# STM32L562 register map
File version: 1.0
CPU: CM33 r0p1, little endian, MPU, FPU, 3 interrupt priority bits
Registers are 32-bit, read-write, reset 0x0 unless marked. A register's access mark holds for its fields unless they carry their own. Offsets are from the block's base; [hi:lo] are bit positions; lines under a group give offsets from that group; {n}, {i} and the like mark numbered series.

## TIM6 — General-purpose-timers
Base 0x40001000
Same registers: TIM7 0x40001400, SEC_TIM6 0x50001000, SEC_TIM7 0x50001400
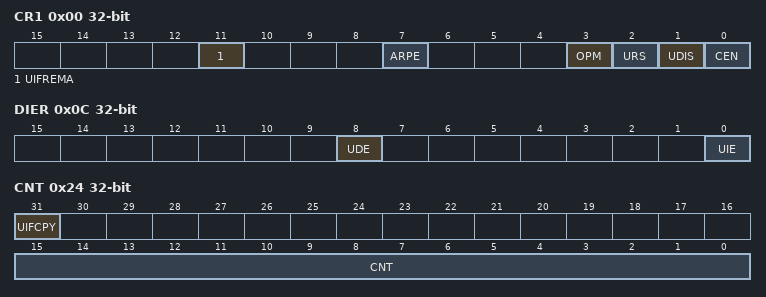
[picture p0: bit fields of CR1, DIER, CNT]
0x00 CR1 — control register 1
  [11] UIFREMA — UIF status bit remapping
  [7] ARPE — Auto-reload preload enable
    0=Disabled (TIMx_APRR register is not buffered); 1=Enabled (TIMx_APRR register is buffered)
  [3] OPM — One-pulse mode
    0=Disabled (Counter is not stopped at update event); 1=Enabled (Counter stops counting at the next update event (clearing the CEN bit))
  [2] URS — Update request source
    0=AnyEvent (Any of counter overflow/underflow, setting UG, or update through slave mode, generates an update interrupt or DMA request); 1=CounterOnly (Only counter overflow/underflow generates an update interrupt or DMA request)
  [1] UDIS — Update disable
    0=Enabled (Update event enabled); 1=Disabled (Update event disabled)
  [0] CEN — Counter enable
    0=Disabled (Counter disabled); 1=Enabled (Counter enabled)
0x04 CR2 — control register 2
  [6:4] MMS — Master mode selection
    0=Reset (Use UG bit from TIMx_EGR register); 1=Enable (Use CNT bit from TIMx_CEN register); 2=Update (Use the update event)
0x0C DIER — DMA/Interrupt enable register
  [8] UDE — Update DMA request enable
    0=Disabled (Update DMA request disabled); 1=Enabled (Update DMA request enabled)
  [0] UIE — Update interrupt enable
    0=Disabled (Update interrupt disabled); 1=Enabled (Update interrupt enabled)
0x10 SR — status register
  [0] UIF write-0-clears — Update interrupt flag
    on read: 0=NoUpdateOccurred; 1=UpdatePending (Update interrupt pending) | on write: 0=Clear flag
0x14 EGR wo — event generation register
  [0] UG — Update generation
    1=Update (Re-initializes the timer counter and generates an update of the registers.)
0x24 CNT — counter
  [31] UIFCPY — UIFCPY or Res
  [15:0] CNT
0x24 CNT16 16-bit (alternate view of CNT) — 16-bit counter register
  [15:0] CNT — counter value
0x28 PSC — prescaler
  [15:0] PSC — Prescaler value
0x2C ARR reset 0xFFFF — auto-reload register
  [15:0] ARR — ARR_bit0

## TSC — Touch sensing controller
Base 0x40024000
Same registers: SEC_TSC 0x50024000
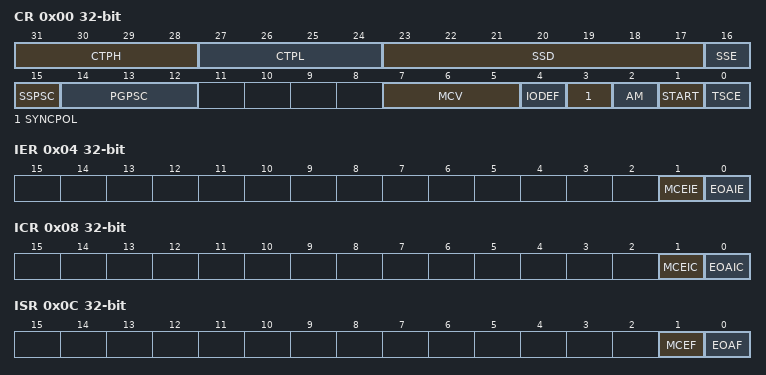
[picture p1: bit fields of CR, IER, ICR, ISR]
0x00 CR — control register
  [31:28] CTPH — Charge transfer pulse high
  [27:24] CTPL — Charge transfer pulse low
  [23:17] SSD — Spread spectrum deviation
  [16] SSE — Spread spectrum enable
    0=Disabled (Spread spectrum disabled); 1=Enabled (Spread spectrum enabled)
  [15] SSPSC — Spread spectrum prescaler
  [14:12] PGPSC — pulse generator prescaler
  [7:5] MCV — Max count value
  [4] IODEF — I/O Default mode
    0=PushPull (I/Os are forced to output push-pull low); 1=Floating (I/Os are in input floating)
  [3] SYNCPOL — Synchronization pin polarity
    0=Falling edge only; 1=Rising edge and high level
  [2] AM — Acquisition mode
    0=Normal acquisition mode (acquisition starts as soon as START bit is set); 1=Synchronized acquisition mode (acquisition starts if START bit is set and when the selected signal is detected on the SYNC input pin)
  [1] START — Start a new acquisition
    0=NoStarted (Acquisition not started); 1=Started (Start a new acquisition)
  [0] TSCE — Touch sensing controller enable
    0=Disabled (Touch sensing controller disabled); 1=Enabled (Touch sensing controller enabled)
0x04 IER — interrupt enable register
  [1] MCEIE — Max count error interrupt enable
    0=Disabled (Max count error interrupt disabled); 1=Enabled (Max count error interrupt enabled)
  [0] EOAIE — End of acquisition interrupt enable
    0=Disabled (End of acquisition interrupt disabled); 1=Enabled (End of acquisition interrupt enabled)
0x08 ICR — interrupt clear register
  [1] MCEIC — Max count error interrupt clear
  [0] EOAIC — End of acquisition interrupt clear
0x0C ISR — interrupt status register
  [1] MCEF — Max count error flag
  [0] EOAF — End of acquisition flag
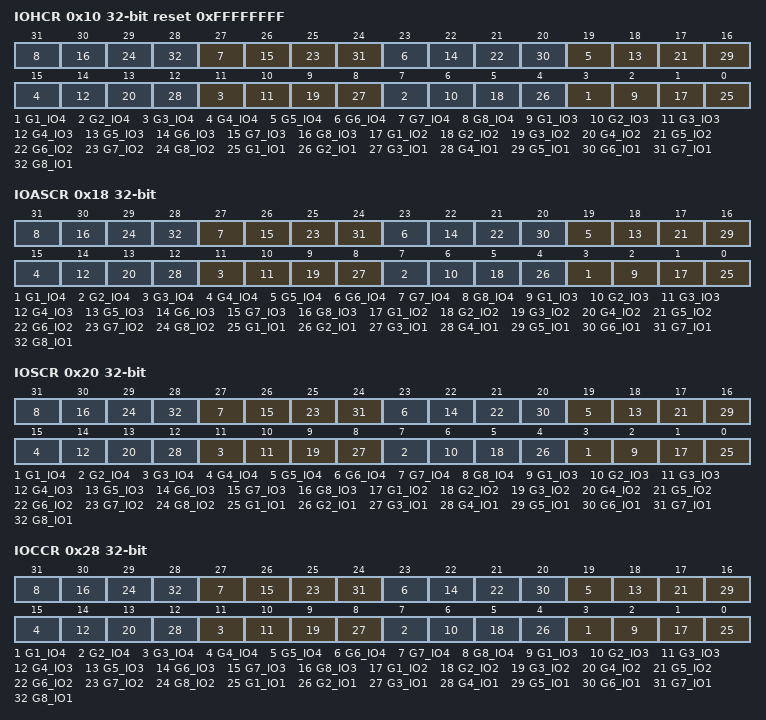
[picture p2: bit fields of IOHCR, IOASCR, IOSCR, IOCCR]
0x10 IOHCR reset 0xFFFFFFFF — I/O hysteresis control register
  [all] fields
    0=Disabled (Gx_IOy Schmitt trigger hysteresis disabled); 1=Enabled (Gx_IOy Schmitt trigger hysteresis enabled)
  [4n-1] G{n}_IO4 (n=1..8) — G{n}_IO4
  [4n-2] G{n}_IO3 (n=1..8) — G{n}_IO3
  [4n-3] G{n}_IO2 (n=1..8) — G{n}_IO2
  [4n-4] G{n}_IO1 (n=1..8) — G{n}_IO1
0x18 IOASCR — I/O analog switch control register
  [all] fields
    0=Disabled (Gx_IOy analog switch disabled (opened)); 1=Enabled (Gx_IOy analog switch enabled (closed))
  [4n-1] G{n}_IO4 (n=1..8) — G{n}_IO4
  [4n-2] G{n}_IO3 (n=1..8) — G{n}_IO3
  [4n-3] G{n}_IO2 (n=1..8) — G{n}_IO2
  [4n-4] G{n}_IO1 (n=1..8) — G{n}_IO1
0x20 IOSCR — I/O sampling control register
  [all] fields
    0=Disabled (Gx_IOy unused); 1=Enabled (Gx_IOy used as sampling capacitor)
  [4n-1] G{n}_IO4 (n=1..8) — G{n}_IO4
  [4n-2] G{n}_IO3 (n=1..8) — G{n}_IO3
  [4n-3] G{n}_IO2 (n=1..8) — G{n}_IO2
  [4n-4] G{n}_IO1 (n=1..8) — G{n}_IO1
0x28 IOCCR — I/O channel control register
  [all] fields
    0=Disabled (Gx_IOy unused); 1=Enabled (Gx_IOy used as channel)
  [4n-1] G{n}_IO4 (n=1..8) — G{n}_IO4
  [4n-2] G{n}_IO3 (n=1..8) — G{n}_IO3
  [4n-3] G{n}_IO2 (n=1..8) — G{n}_IO2
  [4n-4] G{n}_IO1 (n=1..8) — G{n}_IO1
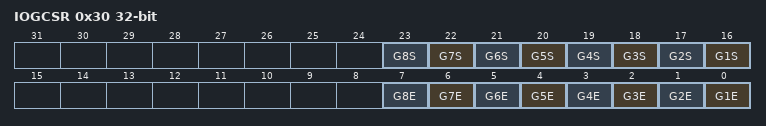
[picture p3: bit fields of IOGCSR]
0x30 IOGCSR access per field — I/O group control status register
  [n+15] G{n}S (n=1..8) ro — Analog I/O group x status
    0=Ongoing (Acquisition on analog I/O group x is ongoing or not started); 1=Complete (Acquisition on analog I/O group x is complete)
  [n-1] G{n}E (n=1..8) rw — Analog I/O group x enable
    0=Disabled (Acquisition on analog I/O group x disabled); 1=Enabled (Acquisition on analog I/O group x enabled)
{0x30+4i} IOG{i}CR (i=1..8) ro — I/O group x counter register
  [13:0] CNT — Counter value

## VREFBUF — Voltage reference buffer
Base 0x40010030
Same registers: SEC_VREFBUF 0x50010030
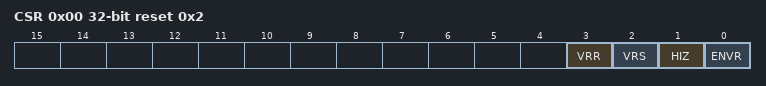
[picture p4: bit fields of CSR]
0x00 CSR access per field reset 0x2 — VREF control and status register
  [3] VRR ro — Voltage reference buffer ready
  [2] VRS rw — Voltage reference scale
  [1] HIZ rw — High impedance mode
  [0] ENVR rw — Voltage reference buffer enable
0x04 CCR — calibration control register
  [5:0] TRIM — Trimming code

## WWDG — System window watchdog
Base 0x40002C00
Same registers: SEC_WWDG 0x50002C00
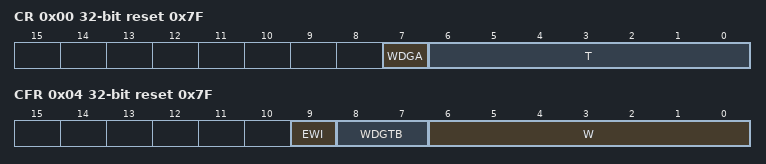
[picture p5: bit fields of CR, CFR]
0x00 CR reset 0x7F — Control register
  [7] WDGA — Activation bit
    0=Disabled (Watchdog disabled); 1=Enabled (Watchdog enabled)
  [6:0] T — 7-bit counter (MSB to LSB)
0x04 CFR reset 0x7F — Configuration register
  [9] EWI — Early wakeup interrupt
    on write: 1=Enable (interrupt occurs whenever the counter reaches the value 0x40)
  [8:7] WDGTB — Timer base
    0=Div1 (Counter clock (PCLK1 div 4096) div 1); 1=Div2 (Counter clock (PCLK1 div 4096) div 2); 2=Div4 (Counter clock (PCLK1 div 4096) div 4); 3=Div8 (Counter clock (PCLK1 div 4096) div 8)
  [6:0] W — 7-bit window value
0x08 SR — Status register
  [0] EWIF write-0-clears — Early wakeup interrupt flag
    on read: 0=Finished (The EWI Interrupt Service Routine has been serviced); 1=Pending (The EWI Interrupt Service Routine has been triggered) | on write: 0=Finished (The EWI Interrupt Service Routine has been serviced)
